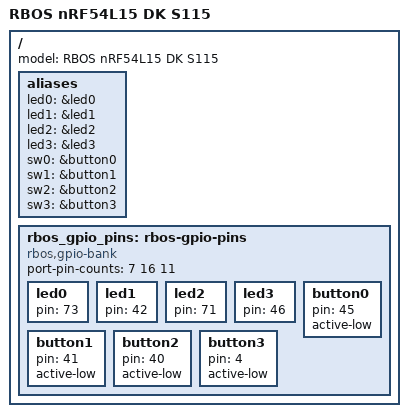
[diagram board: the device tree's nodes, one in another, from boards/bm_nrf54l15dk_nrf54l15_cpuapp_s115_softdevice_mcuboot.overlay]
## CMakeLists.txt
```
cmake_minimum_required(VERSION 3.20.0)

list(PREPEND EXTRA_CONF_FILE "${CMAKE_CURRENT_SOURCE_DIR}/common.conf")
find_package(Zephyr REQUIRED HINTS $ENV{ZEPHYR_BASE})
project(rbos)
zephyr_include_directories(include)

if(NOT DEFINED SYSBUILD)
  message(FATAL_ERROR "This must be built with sysbuild.")
endif()
if(NOT CONFIG_BOARD_BM_NRF54L15DK_NRF54L15_CPUAPP_S115_SOFTDEVICE_MCUBOOT)
  message(FATAL_ERROR "RBOS requires the nRF54L15 DK S115 MCUboot board target.")
endif()
if(NOT CONFIG_MCUBOOT_BOOTLOADER_MODE_FIRMWARE_UPDATER)
  message(FATAL_ERROR "Invalid MCUboot mode selected.")
endif()

zephyr_get(RBOS_PREFLIGHT SYSBUILD LOCAL)
if(RBOS_PREFLIGHT)
  target_sources(app PRIVATE ../tools/bm-build/preflight.c)
  return()
endif()

if(CONFIG_LTO OR CMAKE_INTERPROCEDURAL_OPTIMIZATION OR
   "${CMAKE_C_FLAGS} ${CMAKE_C_FLAGS_DEBUG} ${CMAKE_C_FLAGS_RELEASE}" MATCHES "-flto")
  message(FATAL_ERROR "RBOS supervisor requires separate translation units: LTO is unsupported")
endif()
foreach(config DEBUG RELEASE RELWITHDEBINFO MINSIZEREL)
  if(CMAKE_INTERPROCEDURAL_OPTIMIZATION_${config} OR CMAKE_C_FLAGS_${config} MATCHES "-flto")
    message(FATAL_ERROR "RBOS supervisor requires separate translation units: LTO is unsupported")
  endif()
endforeach()
include(cmake/mrubyc.cmake)
zephyr_ld_options(-Wl,--wrap=mrbc_vm_run)
target_include_directories(app PRIVATE ../src/platform/nrf)
target_sources(app PRIVATE ../src/platform/nrf/backend.c)
target_sources(app PRIVATE ../src/platform/nrf/adc.c)
target_sources(app PRIVATE ../src/platform/nrf/gpio.c)
target_sources(app PRIVATE ../src/platform/nrf/button.c)
target_sources(app PRIVATE src/main.c src/runtime.c src/ble.c src/resources.c src/hal/hal.c)
target_sources(app PRIVATE src/resource_probe.c)
target_sources(app PRIVATE src/supervisor.c)
target_sources(app PRIVATE src/ble_name.c)
target_sources(app PRIVATE src/mcumgr_reset.c)
target_sources(app PRIVATE src/fatal.c)
target_sources(app PRIVATE ../src/platform/nrf/wdt.c)
target_sources_ifdef(CONFIG_RBOS_SATURATION_FIXTURE app PRIVATE src/saturation_fixture.c)
target_sources_ifdef(CONFIG_RBOS_RETENTION_FIXTURE app PRIVATE src/retention_fixture.c)
```

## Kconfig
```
config NRFX_RESERVED_RESOURCES_HEADER
	default "rbos_reserved_resources.h"

menu "RBOS application"

config RBOS_BLE_NAME_PREFIX
	string "BLE device name prefix (1-21 bytes)"
	default "RBOS"
	help
	  Prefix for the DEVICEID-derived name. The suffix uses five bytes.
	  Names must fit legacy advertising with the three-byte Flags field.
	  Empty or overlong prefixes are rejected during BLE initialization.

config RBOS_WDT
	bool "Foreground progress watchdog"
	default y
	select NRFX_WDT

config RBOS_WDT_TIMEOUT_MS
	int "Watchdog timeout (ms)"
	range 100 60000
	default 2000

config RBOS_FATAL_REBOOT
	bool "Reboot after fatal instead of halting"
	select REBOOT
	depends on RBOS_WDT

config RBOS_FATAL_FLUSH_MS
	int "Fatal log flush deadline (ms)"
	range 1 1000
	default 100

config RBOS_FAULT_WDT
	bool "Stall native supervisor to exercise watchdog reset"
	depends on RBOS_WDT && DEBUG_OPTIMIZATIONS && !RBOS_FATAL_REBOOT
	default n

config RBOS_GPIO
	bool "RBOS board GPIO and Button API"
	default y

config RBOS_PERIPHERAL_EXERCISE
	bool "Run the P2 LED/Button diagnostic task after selftests"
	default y
	depends on RBOS_GPIO && !RBOS_TEST_PROFILE_OOM

config RBOS_SATURATION_FIXTURE
	bool "A7 TIMER/PORT and synthetic ring saturation fixture"
	depends on RBOS_GPIO && !RBOS_TEST_PROFILE_OOM && !RBOS_FAULT_WDT
	select NRFX_TIMER
	select NRFX_GPPI
	default n

config RBOS_RETENTION_FIXTURE
	bool "A7 storage0 retention fixture"
	depends on !RBOS_TEST_PROFILE_OOM && !RBOS_FAULT_WDT
	select BM_STORAGE
	select RING_BUFFER
	select CRC
	default n

config RBOS_RETENTION_SEED
	bool "Allow one explicit seed with physical Button1 held at boot"
	depends on RBOS_RETENTION_FIXTURE
	default n

config RBOS_RETENTION_NONCE
	hex "Retention trial identifier (same nonzero value in images A and B)"
	depends on RBOS_RETENTION_FIXTURE
	default 0

choice RBOS_TEST_PROFILE
	prompt "Ruby test profile"
	default RBOS_TEST_PROFILE_SELFTEST

config RBOS_TEST_PROFILE_SELFTEST
	bool "User selftests"

config RBOS_TEST_PROFILE_STRESS
	bool "Selftests followed by always-ready spinners"

config RBOS_TEST_PROFILE_OOM
	bool "Retained allocations until fatal pool exhaustion"

endchoice

config RBOS_MAX_VM_COUNT
	int "Maximum number of Ruby VMs"
	range 4 32
	default 8

config RBOS_VM_POOL_SIZE
	int "Ruby VM memory pool size"
	range 16384 131072
	default 65536

config RBOS_TIMESLICE_TICK_COUNT
	int "Ruby VM timeslice (ticks)"
	range 1 255
	default 1

config RBOS_SERVICE_INTERVAL_MS
	int "Native supervisor interval (ms)"
	range 1 1000
	default 10

config RBOS_STATS_INTERVAL_MS
	int "Runtime statistics interval (ms)"
	range 100 3600000
	default 10000

config RBOS_VM_NDEBUG
	bool "Disable assertions in mruby/c sources"

module=RBOS
module-str=RBOS
source "$(ZEPHYR_BASE)/subsys/logging/Kconfig.template.log_config"

endmenu

source "Kconfig.zephyr"
```

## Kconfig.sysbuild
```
source "$(ZEPHYR_BASE)/share/sysbuild/Kconfig"

config RBOS_RELEASE
 bool "Require an external release signing key"
 default n
```

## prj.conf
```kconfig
CONFIG_DEBUG_OPTIMIZATIONS=y
CONFIG_RBOS_FATAL_REBOOT=n
```

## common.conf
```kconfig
CONFIG_LOG=y
CONFIG_LOG_BACKEND_BM_UARTE=y
CONFIG_CLOCK_CONTROL=y
CONFIG_NRFX_SAADC=y
CONFIG_NRFX_GPIOTE=y
CONFIG_NRFX_GPIOTE_NUM_OF_EVT_HANDLERS=4
CONFIG_SOFTDEVICE=y
CONFIG_CRC=y
CONFIG_MAIN_STACK_SIZE=8192
CONFIG_INIT_STACKS=y
CONFIG_BM_TIMER=y
CONFIG_BM_SCHEDULER=y
CONFIG_NRF_SDH_DISPATCH_MODEL_SCHED=y
CONFIG_BM_SCHEDULER_BUF_SIZE=512
CONFIG_NRF_SDH_BLE_LOG_SD_RAM_USAGE=y
CONFIG_NRF_SECURITY=y
CONFIG_MBEDTLS_PSA_CRYPTO_C=y
CONFIG_PSA_WANT_GENERATE_RANDOM=y
CONFIG_BLE_ADV=y
CONFIG_BLE_ADV_RESTART_ON_DISCONNECT=y
CONFIG_BLE_ADV_FAST_ADVERTISING=y
CONFIG_BLE_ADV_FAST_ADVERTISING_TIMEOUT=1000
CONFIG_BLE_ADV_SLOW_ADVERTISING=y
CONFIG_BLE_ADV_SLOW_ADVERTISING_TIMEOUT=0
CONFIG_BLE_CONN_PARAMS=y
CONFIG_BLE_CONN_PARAMS_AUTO_ATT_MTU=y
CONFIG_NRF_SDH_BLE_GATT_MAX_MTU_SIZE=247
CONFIG_BLE_CONN_PARAMS_INITIATE_ATT_MTU_EXCHANGE=n
CONFIG_BLE_CONN_PARAMS_AUTO_DATA_LENGTH=y
CONFIG_BLE_CONN_PARAMS_DATA_LENGTH_TX=251
CONFIG_BLE_CONN_PARAMS_DATA_LENGTH_RX=251
CONFIG_BLE_CONN_PARAMS_INITIATE_DATA_LENGTH_UPDATE=n
CONFIG_BLE_CONN_PARAMS_AUTO_GAP_CONN_PARAM_UPDATE=n
CONFIG_BLE_CONN_PARAMS_LOG_LEVEL_WRN=y

CONFIG_NRF_SDH_BLE_VS_UUID_COUNT=2
CONFIG_ZCBOR=y
CONFIG_NET_BUF=y
CONFIG_ZEPHYR_QUEUE=y
CONFIG_NCS_BM_MCUMGR=y
CONFIG_BLE_MCUMGR=y
CONFIG_MCUBOOT_BOOTUTIL_LIB=y
CONFIG_MCUMGR_TRANSPORT_REASSEMBLY=y
CONFIG_MCUMGR_MGMT_NOTIFICATION_HOOKS=y
CONFIG_MCUMGR_GRP_OS=y
CONFIG_MCUMGR_GRP_OS_RESET_HOOK=y
CONFIG_MCUMGR_GRP_OS_RESET_BOOT_MODE=n
CONFIG_MCUMGR_GRP_OS_ECHO=n
CONFIG_MCUMGR_GRP_OS_MCUMGR_PARAMS=n
CONFIG_MCUMGR_GRP_OS_BOOTLOADER_INFO=n
CONFIG_MCUMGR_GRP_OS_INFO=n
CONFIG_MCUMGR_GRP_IMG=n
CONFIG_MCUMGR_GRP_SETTINGS=n
CONFIG_RETAINED_MEM=y
CONFIG_RETENTION=y
CONFIG_RETENTION_BOOT_MODE=y
CONFIG_REBOOT=y
```

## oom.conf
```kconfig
CONFIG_RBOS_TEST_PROFILE_OOM=y
```

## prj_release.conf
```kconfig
CONFIG_SIZE_OPTIMIZATIONS=y
CONFIG_RBOS_FATAL_REBOOT=y
CONFIG_RBOS_VM_NDEBUG=y
```

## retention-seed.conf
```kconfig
CONFIG_RBOS_RETENTION_FIXTURE=y
CONFIG_RBOS_RETENTION_SEED=y
CONFIG_RBOS_PERIPHERAL_EXERCISE=n
```

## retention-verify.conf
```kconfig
CONFIG_RBOS_RETENTION_FIXTURE=y
CONFIG_RBOS_PERIPHERAL_EXERCISE=n
```

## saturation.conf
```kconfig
CONFIG_RBOS_SATURATION_FIXTURE=y
CONFIG_RBOS_PERIPHERAL_EXERCISE=n
```

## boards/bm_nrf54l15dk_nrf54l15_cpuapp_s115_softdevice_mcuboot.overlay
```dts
/ {
	model = "RBOS nRF54L15 DK S115";
	aliases {
		led0 = &led0;
		led1 = &led1;
		led2 = &led2;
		led3 = &led3;
		sw0 = &button0;
		sw1 = &button1;
		sw2 = &button2;
		sw3 = &button3;
	};
	rbos_gpio_pins: rbos-gpio-pins {
		compatible = "rbos,gpio-bank";
		port-pin-counts = <7 16 11>;
		led0: led0 { pin = <73>; };
		led1: led1 { pin = <42>; };
		led2: led2 { pin = <71>; };
		led3: led3 { pin = <46>; };
		button0: button0 { pin = <45>; active-low; };
		button1: button1 { pin = <41>; active-low; };
		button2: button2 { pin = <40>; active-low; };
		button3: button3 { pin = <4>; active-low; };
	};
};
```

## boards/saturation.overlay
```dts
&button0 {
	pin = <43>;
};
```

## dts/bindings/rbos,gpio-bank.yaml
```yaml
description: RBOS native GPIO metadata (no Zephyr GPIO driver)
compatible: "rbos,gpio-bank"
properties:
  port-pin-counts:
    type: array
    required: true
child-binding:
  description: Board-reviewed native pin
  properties:
    pin:
      type: int
      required: true
    active-low:
      type: boolean
```

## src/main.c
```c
#include <app_version.h>
#include <zephyr/kernel.h>
#include <zephyr/logging/log.h>
#include <zephyr/logging/log_ctrl.h>
#include "mrubyc.h"
#include "rbos/bindings.h"
#include "backend.h"
#include "embedded.h"
#include "runtime.h"
#include "supervisor.h"
#include "status_led.h"
#include "rbos/watchdog.h"
#include "rbos_fixture.h"

LOG_MODULE_REGISTER(rbos, CONFIG_RBOS_LOG_LEVEL);
static uint8_t vm_pool[CONFIG_RBOS_VM_POOL_SIZE] __aligned(8);

int main(void)
{
	rbos_stack_paint();
	LOG_INF("RBOS %s", APP_VERSION_EXTENDED_STRING);
	rbos_reset_reason_log();
	rbos_status_led(true);

	if (rbos_resources_probe()) mrbc_hal_abort("BM scheduler capacity probe failed\n");
	if (rbos_ble_init()) mrbc_hal_abort("BLE initialization failed\n");
#if defined(CONFIG_RBOS_RETENTION_FIXTURE)
	rbos_retention_start();
#endif
	rbos_resources_log();
	mrbc_init(vm_pool, sizeof(vm_pool));
	rbos_define_classes(rbos_nrf_backend());
	for (unsigned int i = 0; i < rbos_task_count; ++i) {
		mrbc_tcb *task = mrbc_create_task(rbos_tasks[i].bytecode, NULL);
		if (!task) mrbc_hal_abort("Cannot create embedded task\n");
		mrbc_set_task_name(task, rbos_tasks[i].name);
	}
	if (rbos_supervisor_start()) mrbc_hal_abort("Cannot start watchdog\n");
	rbos_status_led(false);
	int status = mrbc_run();
	LOG_INF("Ruby scheduler returned %d; native supervisor continues", status);
	while (1) {
		rbos_supervisor_poll(true);
		k_cpu_idle();
	}
}
```

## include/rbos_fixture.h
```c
#ifndef RBOS_FIXTURE_H
#define RBOS_FIXTURE_H

#include <stdbool.h>
#include <stdint.h>

#if defined(CONFIG_RBOS_SATURATION_FIXTURE)
#include <zephyr/devicetree.h>
#define RBOS_FIXTURE_PIN DT_PROP(DT_ALIAS(sw0), pin)
int rbos_fixture_connect(uint32_t task_address);
void rbos_fixture_disconnect(void);
void rbos_fixture_begin(uint32_t pin, uint32_t generation);
void rbos_fixture_irq(void);
void rbos_fixture_edge(uint32_t pin, uint32_t level, bool accepted);
void rbos_fixture_delivery(uint32_t pin, uint32_t level, uint32_t count);
bool rbos_fixture_holds_events(void);
void rbos_fixture_poll(void);
#endif

#if defined(CONFIG_RBOS_RETENTION_FIXTURE)
void rbos_retention_start(void);
void rbos_retention_poll(void);
#endif

#endif
```

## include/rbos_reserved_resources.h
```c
#ifndef RBOS_RESERVED_RESOURCES_H
#define RBOS_RESERVED_RESOURCES_H

#include <nrf_sd_def.h>

#if !defined(CONFIG_SOFTDEVICE_S115) || defined(CONFIG_BT_LL_SOFTDEVICE) || defined(CONFIG_MPSL)
#error "RBOS resource reservations require the standalone S115 SoftDevice"
#endif

#define NRFX_DPPI00_CHANNELS_USED_BY_BT_CTLR SD_DPPIC00_CHANNELS_USED
#define NRFX_DPPI10_CHANNELS_USED_BY_BT_CTLR SD_DPPIC10_CHANNELS_USED
#define NRFX_DPPI20_CHANNELS_USED_BY_BT_CTLR SD_DPPIC20_CHANNELS_USED
#define NRFX_PPIB_00_10_CHANNELS_USED_BY_BT_CTLR \
  (SD_PPIB00_CHANNELS_USED | SD_PPIB10_CHANNELS_USED)
#define NRFX_PPIB_11_21_CHANNELS_USED_BY_BT_CTLR \
  (SD_PPIB11_CHANNELS_USED | SD_PPIB21_CHANNELS_USED)

#include <nrfx_reserved_resources_ncs.h>

#endif
```

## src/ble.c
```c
#include <string.h>
#include <hal/nrf_ficr.h>
#include <ble_gatts.h>
#include <bm/bluetooth/ble_adv.h>
#include <bm/bluetooth/services/ble_mcumgr.h>
#include <bm/softdevice_handler/nrf_sdh.h>
#include <bm/softdevice_handler/nrf_sdh_ble.h>
#include <zephyr/logging/log.h>
#include "runtime.h"
#include "rbos/ble_name.h"
#include "mcumgr_reset.h"

LOG_MODULE_REGISTER(rbos_ble, CONFIG_RBOS_LOG_LEVEL);
BLE_ADV_DEF(advertising);

static void on_ble_event(const ble_evt_t *evt, void *context)
{
	ARG_UNUSED(context);
	uint32_t result = NRF_SUCCESS;
	switch (evt->header.evt_id) {
	case BLE_GAP_EVT_CONNECTED:
		LOG_INF("BLE connected");
		rbos_mcumgr_connected(evt->evt.gap_evt.conn_handle);
		break;
	case BLE_GAP_EVT_DISCONNECTED:
		LOG_INF("BLE disconnected reason=0x%02x", evt->evt.gap_evt.params.disconnected.reason);
		rbos_mcumgr_disconnected(evt->evt.gap_evt.conn_handle);
		break;
	case BLE_GATTS_EVT_HVN_TX_COMPLETE:
		rbos_mcumgr_notification_sent(evt->evt.gatts_evt.conn_handle);
		break;
	case BLE_GAP_EVT_PHY_UPDATE_REQUEST:
		LOG_INF("BLE PHY request tx=0x%02x rx=0x%02x",
			evt->evt.gap_evt.params.phy_update_request.peer_preferred_phys.tx_phys,
			evt->evt.gap_evt.params.phy_update_request.peer_preferred_phys.rx_phys);
		break;
	case BLE_GAP_EVT_PHY_UPDATE:
		LOG_INF("BLE PHY update status=0x%02x", evt->evt.gap_evt.params.phy_update.status);
		break;
	case BLE_GAP_EVT_DATA_LENGTH_UPDATE_REQUEST:
		LOG_INF("BLE data length request tx=%u rx=%u",
			evt->evt.gap_evt.params.data_length_update_request.peer_params.max_tx_octets,
			evt->evt.gap_evt.params.data_length_update_request.peer_params.max_rx_octets);
		break;
	case BLE_GAP_EVT_DATA_LENGTH_UPDATE:
		LOG_INF("BLE data length updated tx=%u rx=%u",
			evt->evt.gap_evt.params.data_length_update.effective_params.max_tx_octets,
			evt->evt.gap_evt.params.data_length_update.effective_params.max_rx_octets);
		break;
	case BLE_GATTS_EVT_EXCHANGE_MTU_REQUEST:
		LOG_INF("BLE ATT MTU request rx=%u", evt->evt.gatts_evt.params.exchange_mtu_request.client_rx_mtu);
		break;
	case BLE_GATTS_EVT_SYS_ATTR_MISSING:
		LOG_INF("BLE system attributes missing");
		result = sd_ble_gatts_sys_attr_set(evt->evt.gatts_evt.conn_handle, NULL, 0, 0);
		break;
	case BLE_GAP_EVT_SEC_PARAMS_REQUEST:
		LOG_INF("BLE security parameters requested; pairing unsupported");
		result = sd_ble_gap_sec_params_reply(evt->evt.gap_evt.conn_handle,
			BLE_GAP_SEC_STATUS_PAIRING_NOT_SUPP, NULL, NULL);
		break;
	case BLE_GAP_EVT_SEC_INFO_REQUEST:
		LOG_INF("BLE security information requested; no stored bond");
		result = sd_ble_gap_sec_info_reply(evt->evt.gap_evt.conn_handle, NULL);
		break;
	case BLE_GATTS_EVT_TIMEOUT:
		LOG_INF("BLE GATTS timeout source=%u", evt->evt.gatts_evt.params.timeout.src);
		break;
	default:
		break;
	}
	if (result) LOG_ERR("BLE reply event=0x%04x error=%#x", evt->header.evt_id, result);
}
NRF_SDH_BLE_OBSERVER(rbos_ble, on_ble_event, NULL, USER_LOW);

static void on_adv_event(struct ble_adv *adv, const struct ble_adv_evt *evt)
{
	ARG_UNUSED(adv);
	if (evt->evt_type == BLE_ADV_EVT_ERROR) LOG_ERR("Advertising error %#x", evt->error.reason);
}

int rbos_ble_init(void)
{
	int err = nrf_sdh_enable_request();
	if (err) return err;
	err = nrf_sdh_ble_enable(CONFIG_NRF_SDH_BLE_CONN_TAG);
	if (err) return err;
	ble_gap_conn_sec_mode_t security;
	BLE_GAP_CONN_SEC_MODE_SET_NO_ACCESS(&security);
	uint8_t device_id[8];
	char name[RBOS_BLE_NAME_CAPACITY];
	rbos_ble_device_id_bytes(nrf_ficr_deviceid_get(NRF_FICR, 0),
	                         nrf_ficr_deviceid_get(NRF_FICR, 1), device_id);
	err = rbos_ble_name_generate(name, sizeof(name), CONFIG_RBOS_BLE_NAME_PREFIX, device_id);
	if (err) return err;
	uint32_t result = sd_ble_gap_device_name_set(&security, name, strlen(name));
	if (result) return -EIO;
	err = rbos_mcumgr_init();
	if (err) return err;
	ble_uuid_t uuid = {
		.uuid = BLE_MCUMGR_SERVICE_UUID_SUB,
		.type = ble_mcumgr_service_uuid_type(),
	};
	struct ble_adv_config config = {
		.conn_cfg_tag = CONFIG_NRF_SDH_BLE_CONN_TAG,
		.evt_handler = on_adv_event,
		.adv_data = {
			.name_type = BLE_ADV_DATA_FULL_NAME,
			.flags = BLE_GAP_ADV_FLAGS_LE_ONLY_GENERAL_DISC_MODE,
		},
		.sr_data.uuid_lists.complete = { .uuid = &uuid, .len = 1 },
	};
	result = ble_adv_init(&advertising, &config);
	if (result) return -EIO;
	result = ble_adv_start(&advertising, BLE_ADV_MODE_FAST);
	return result ? -EIO : 0;
}
```

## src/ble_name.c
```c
#include <errno.h>
#include <stdio.h>
#include <string.h>
#include <zephyr/sys/crc.h>
#include "rbos/ble_name.h"

void rbos_ble_device_id_bytes(uint32_t word0, uint32_t word1, uint8_t bytes[8])
{
	for (unsigned int i = 0; i < 4; ++i) {
		bytes[i] = word1 >> (24 - 8 * i);
		bytes[4 + i] = word0 >> (24 - 8 * i);
	}
}

int rbos_ble_name_generate(char *name, size_t capacity, const char *prefix,
                          const uint8_t device_id[8])
{
	if (!name || !prefix || !device_id) return -EINVAL;
	size_t length = strlen(prefix);
	if (!length || length > RBOS_BLE_NAME_MAX_PREFIX) return -EINVAL;
	if (capacity < length + 6) return -ENOSPC;
	uint16_t crc = crc16_reflect(0x9eb2, 0xffff, device_id, 8);
	int result = snprintf(name, capacity, "%s_%04X", prefix, (unsigned int)crc);
	return result < 0 ? -EIO : 0;
}
```

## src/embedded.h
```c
#ifndef RBOS_EMBEDDED_H
#define RBOS_EMBEDDED_H
#include <stdint.h>
struct rbos_embedded_task {
	const char *name;
	const uint8_t *bytecode;
};
extern const struct rbos_embedded_task rbos_tasks[];
extern const unsigned int rbos_task_count;
#endif
```

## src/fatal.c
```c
#include <bm/bm_timer.h>
#include <zephyr/kernel.h>
#include <zephyr/fatal.h>
#include <zephyr/logging/log_ctrl.h>
#include <zephyr/sys/printk.h>
#include <zephyr/sys/reboot.h>
#include "mrubyc.h"
#include "rbos/watchdog.h"
#include "status_led.h"

#if CONFIG_RBOS_FATAL_REBOOT
static struct bm_timer fatal_deadline;

static void fatal_reboot(void *context)
{
	ARG_UNUSED(context);
	sys_reboot(SYS_REBOOT_COLD);
}
#endif

_Noreturn void mrbc_hal_abort(const char *message)
{
	rbos_status_led(true);
#if CONFIG_RBOS_FATAL_REBOOT
	if (bm_timer_init(&fatal_deadline, BM_TIMER_MODE_SINGLE_SHOT, fatal_reboot) ||
	    bm_timer_start(&fatal_deadline, BM_TIMER_MS_TO_TICKS(CONFIG_RBOS_FATAL_FLUSH_MS), NULL))
		sys_reboot(SYS_REBOOT_COLD);
#else
	rbos_wdt_stop();
#endif
	mrbc_hal_flush(2);
	printk("RBOS fatal: %s", message ? message : "Ruby abort\n");
	LOG_PANIC();
#if CONFIG_RBOS_FATAL_REBOOT
	sys_reboot(SYS_REBOOT_COLD);
#else
	k_fatal_halt(K_ERR_KERNEL_PANIC);
#endif
	CODE_UNREACHABLE;
}
```

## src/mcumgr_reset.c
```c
#include <errno.h>
#include <stdbool.h>
#include <ble_gap.h>
#include <bm/bluetooth/services/ble_mcumgr.h>
#include <zephyr/mgmt/mcumgr/mgmt/callbacks.h>
#include <zephyr/retention/bootmode.h>
#include <zephyr/sys/reboot.h>
#include "mcumgr_reset.h"

static uint16_t connected_handle = BLE_CONN_HANDLE_INVALID;
static uint16_t reset_handle = BLE_CONN_HANDLE_INVALID;
static bool pending;
static bool notification_sent;
static bool disconnected;
static bool disconnect_requested;

static enum mgmt_cb_return reset_hook(uint32_t event, enum mgmt_cb_return previous,
                                    int32_t *rc, uint16_t *group, bool *abort_more,
                                    void *data, size_t size)
{
	(void)group;
	(void)data;
	(void)size;
	if (event != MGMT_EVT_OP_OS_MGMT_RESET) return MGMT_CB_OK;
	if (previous != MGMT_CB_OK) return previous;
	*abort_more = true;
	if (pending || connected_handle == BLE_CONN_HANDLE_INVALID) {
		*rc = MGMT_ERR_EBUSY;
	} else if (bootmode_set(BOOT_MODE_TYPE_BOOTLOADER)) {
		*rc = MGMT_ERR_EUNKNOWN;
	} else {
		reset_handle = connected_handle;
		pending = true;
		notification_sent = false;
		disconnected = false;
		disconnect_requested = false;
		*rc = MGMT_ERR_EOK;
	}
	return MGMT_CB_ERROR_RC;
}

static struct mgmt_callback reset_callback = {
	.callback = reset_hook,
	.event_id = MGMT_EVT_OP_OS_MGMT_RESET,
};

int rbos_mcumgr_init(void)
{
	struct ble_mcumgr_config config = {
		.sec_mode = BLE_MCUMGR_CONFIG_SEC_MODE_DEFAULT,
	};
	if (ble_mcumgr_init(&config)) return -EIO;
	mgmt_callback_register(&reset_callback);
	return 0;
}

void rbos_mcumgr_connected(uint16_t handle)
{
	connected_handle = handle;
}

void rbos_mcumgr_disconnected(uint16_t handle)
{
	if (handle == connected_handle) connected_handle = BLE_CONN_HANDLE_INVALID;
	if (pending && handle == reset_handle) disconnected = true;
}

void rbos_mcumgr_notification_sent(uint16_t handle)
{
	if (pending && handle == reset_handle) notification_sent = true;
}

void rbos_mcumgr_poll(void)
{
	if (!pending) return;
	if (disconnected) {
		pending = false;
		sys_reboot(SYS_REBOOT_WARM);
		return;
	}
	if (!notification_sent || disconnect_requested) return;
	uint32_t result = sd_ble_gap_disconnect(reset_handle,
		BLE_HCI_REMOTE_USER_TERMINATED_CONNECTION);
	if (result == NRF_SUCCESS) disconnect_requested = true;
}
```

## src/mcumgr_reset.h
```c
#ifndef RBOS_MCUMGR_RESET_H
#define RBOS_MCUMGR_RESET_H

#include <stdint.h>

int rbos_mcumgr_init(void);
void rbos_mcumgr_connected(uint16_t handle);
void rbos_mcumgr_disconnected(uint16_t handle);
void rbos_mcumgr_notification_sent(uint16_t handle);
void rbos_mcumgr_poll(void);

#endif
```

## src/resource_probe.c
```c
#include <errno.h>
#include <string.h>
#include <bm/bm_scheduler.h>
#include <zephyr/logging/log.h>
#include "runtime.h"

LOG_MODULE_REGISTER(rbos_probe, CONFIG_RBOS_LOG_LEVEL);
static unsigned int delivered;
static bool corrupt;
static uint8_t payload[64];

static void consume(void *data, size_t length)
{
  ++delivered;
  if (length && memcmp(data, payload, length)) corrupt = true;
}

int rbos_resources_probe(void)
{
  /* Run before SoftDevice enable and VM creation, never against a live SD queue. */
  memset(payload, 0xa5, sizeof(payload));
  const size_t lengths[] = { 0, 16, 64 };
  for (unsigned int i = 0; i < 3; ++i) {
    size_t length = lengths[i];
    unsigned int accepted = 0;
    delivered = 0;
    corrupt = false;
    int result = 0;
    for (; accepted < 64; ++accepted) {
      result = bm_scheduler_defer(consume, length ? payload : NULL, length);
      if (result) break;
    }
    bm_scheduler_process();
    bool valid = (result == -ENOMEM || (result == 0 && accepted == 64)) &&
      accepted > 0 && delivered == accepted && !corrupt;
    if (!bm_scheduler_defer(consume, length ? payload : NULL, length)) {
      bm_scheduler_process();
      valid = valid && delivered == accepted + 1 && !corrupt;
    } else valid = false;
    LOG_INF("scheduler_probe payload=%u accepted=%u delivered=%u exhausted=%u recovered=%u",
      (unsigned int)length, accepted, delivered, result == -ENOMEM, valid);
    if (!valid) return -EIO;
  }
  return 0;
}
```

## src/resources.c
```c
#include <bm/bm_irq.h>
#include <bm/bm_scheduler.h>
#include <bm/softdevice_handler/nrf_sdh_ble.h>
#include <nrfx.h>
#include CONFIG_NRFX_RESERVED_RESOURCES_HEADER
#include <zephyr/logging/log.h>
#include <zephyr/sys/util.h>
#include "runtime.h"

LOG_MODULE_REGISTER(rbos_resources, CONFIG_RBOS_LOG_LEVEL);

BUILD_ASSERT(IS_ENABLED(CONFIG_SOFTDEVICE_S115), "RBOS requires S115");
BUILD_ASSERT(IS_ENABLED(CONFIG_LOG_BACKEND_BM_UARTE), "P2 console requires BM UARTE");
BUILD_ASSERT(!IS_ENABLED(CONFIG_SHELL) && !IS_ENABLED(CONFIG_NFC_T2T_NRFXLIB) &&
             !IS_ENABLED(CONFIG_NFC_T4T_NRFXLIB), "Shell/NFC require a new resource audit");
BUILD_ASSERT(IS_ENABLED(CONFIG_NRF_SDH_DISPATCH_MODEL_SCHED), "RBOS requires SCHED dispatch");
BUILD_ASSERT(IS_ENABLED(CONFIG_BM_SCHEDULER), "RBOS requires the BM scheduler");
BUILD_ASSERT(CONFIG_BM_SCHEDULER_BUF_SIZE >= 512, "BM scheduler heap below audited baseline");
BUILD_ASSERT(IS_ENABLED(CONFIG_ZERO_LATENCY_IRQS) && CONFIG_ZERO_LATENCY_LEVELS == 1 &&
             __NVIC_PRIO_BITS == 3 && BM_IRQ_OFFSET == 2,
             "Ruby HAL requires BASEPRI to mask NVIC priorities 2 through 7");
BUILD_ASSERT(CONFIG_BM_TIMER_IRQ_PRIO >= 2 && CONFIG_BM_TIMER_IRQ_PRIO <= 7,
             "BM timer must use an application IRQ priority");
BUILD_ASSERT(CONFIG_LOG_BACKEND_BM_UARTE_IRQ_PRIO >= 2 &&
             CONFIG_LOG_BACKEND_BM_UARTE_IRQ_PRIO <= 7,
             "Console must use an application IRQ priority");
BUILD_ASSERT((NRFX_GRTC_CONFIG_ALLOWED_CC_CHANNELS_MASK & SD_GRTC_CC_CHANNELS_USED) == 0,
             "GRTC allocator overlaps SoftDevice channels");
BUILD_ASSERT((NRFX_GRTC_CONFIG_ALLOWED_CC_CHANNELS_MASK & BIT(0)) != 0 &&
             (SD_GRTC_CC_CHANNELS_USED & BIT(0)) == 0 && SD_GRTC_IRQn_USED != GRTC_2_IRQn,
             "BM system timer requires GRTC channel 0 and GRTC_2");

#define CHECK_RESERVED(actual, reserved) \
  BUILD_ASSERT(((actual) & (reserved)) == (reserved), "nrfx allocator misses " #reserved)
CHECK_RESERVED(NRFX_DPPI00_CHANNELS_USED, SD_DPPIC00_CHANNELS_USED);
CHECK_RESERVED(NRFX_DPPI10_CHANNELS_USED, SD_DPPIC10_CHANNELS_USED);
CHECK_RESERVED(NRFX_DPPI20_CHANNELS_USED, SD_DPPIC20_CHANNELS_USED);
CHECK_RESERVED(NRFX_PPIB_INTERCONNECT_00_10_CHANNELS_USED,
               SD_PPIB00_CHANNELS_USED | SD_PPIB10_CHANNELS_USED);
CHECK_RESERVED(NRFX_PPIB_INTERCONNECT_11_21_CHANNELS_USED,
               SD_PPIB11_CHANNELS_USED | SD_PPIB21_CHANNELS_USED);

void rbos_resources_log(void)
{
  LOG_INF("resources sched_bytes=%u sched_header=%u service_ms=%u sd_ram=%u",
          (unsigned int)CONFIG_BM_SCHEDULER_BUF_SIZE,
          (unsigned int)sizeof(struct bm_scheduler_event),
          (unsigned int)CONFIG_RBOS_SERVICE_INTERVAL_MS,
          (unsigned int)nrf_sdh_ble_sd_ram_usage_get());
}
```

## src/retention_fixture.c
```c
#include <string.h>
#include <stddef.h>
#include <hal/nrf_gpio.h>
#include <bm/storage/bm_storage.h>
#include <zephyr/devicetree.h>
#include <zephyr/kernel.h>
#include <zephyr/logging/log.h>
#include <zephyr/sys/crc.h>
#include "rbos_fixture.h"

LOG_MODULE_REGISTER(rbos_retention, CONFIG_RBOS_LOG_LEVEL);
#define STORAGE DT_NODELABEL(storage0_partition)
#define PEER DT_NODELABEL(peer_manager_partition)
BUILD_ASSERT(CONFIG_RBOS_RETENTION_NONCE != 0, "Set a unique nonzero trial nonce in both images");
BUILD_ASSERT(IS_ENABLED(CONFIG_BM_STORAGE_BACKEND_SD), "Fixture requires SoftDevice storage");
BUILD_ASSERT(!IS_ENABLED(CONFIG_SETTINGS) && !IS_ENABLED(CONFIG_BM_ZMS), "Not settings/ZMS retention");
BUILD_ASSERT(DT_REG_SIZE(STORAGE) == 4096 && DT_REG_SIZE(PEER) == 4096, "Review partition layout");
BUILD_ASSERT(!IS_ENABLED(CONFIG_RBOS_SATURATION_FIXTURE), "Run A7 fixtures separately");

static struct bm_storage storage;
static uint32_t sentinel[8] __aligned(16);
static uint32_t peer_before;
static volatile bool pending, completed;
static volatile int result;
static int64_t deadline;
static bool finished;

static uint32_t peer_digest(void)
{
	return crc32_ieee((const uint8_t *)(uintptr_t)DT_REG_ADDR(PEER), DT_REG_SIZE(PEER));
}

static void event_handler(struct bm_storage_evt *event)
{
	if (!pending || event->id != BM_STORAGE_EVT_WRITE_RESULT || event->ctx != &storage ||
	    event->addr != 0 || event->len != sizeof(sentinel)) {
		result = -1;
	} else {
		result = event->result;
	}
	completed = true;
}

static void fail(const char *reason)
{
	LOG_ERR("p5 error=%s", reason);
	finished = true;
}

static bool verify(void)
{
	uint32_t actual[8];
	if (bm_storage_read(&storage, 0, actual, sizeof(actual)) ||
	    memcmp(actual, sentinel, sizeof(actual))) {
		fail("sentinel_missing_or_corrupt");
		return false;
	}
	return true;
}

void rbos_retention_start(void)
{
	struct bm_storage_config config = { .evt_handler = event_handler, .api = &bm_storage_sd_api,
		.addr = DT_REG_ADDR(STORAGE), .size = DT_REG_SIZE(STORAGE) };
	if (bm_storage_init(&storage, &config)) { fail("init"); return; }
	sentinel[0] = 0x52424f53;
	sentinel[1] = 1;
	sentinel[2] = CONFIG_RBOS_RETENTION_NONCE;
	sentinel[3] = 0xa7a7a7a7;
	sentinel[4] = 0x13579bdf;
	sentinel[5] = 0x2468ace0;
	sentinel[6] = 32;
	sentinel[7] = crc32_ieee((const uint8_t *)sentinel, sizeof(sentinel) - sizeof(uint32_t));
	peer_before = peer_digest();
	if (IS_ENABLED(CONFIG_RBOS_RETENTION_SEED)) {
		uint32_t pin = DT_PROP(DT_ALIAS(sw1), pin);
		uint32_t local = pin;
		NRF_GPIO_Type *port = nrf_gpio_pin_port_decode(&local);
		uint32_t saved = port->PIN_CNF[local];
		nrf_gpio_cfg_input(pin, NRF_GPIO_PIN_PULLUP);
		bool seed = nrf_gpio_pin_read(pin) == 0;
		port->PIN_CNF[local] = saved;
		if (!seed) { fail("seed_requires_held_button1"); return; }
		pending = true;
		deadline = k_uptime_get() + 10000;
		if (bm_storage_write(&storage, 0, sentinel, sizeof(sentinel), &storage)) fail("write_submit");
	}
}

void rbos_retention_poll(void)
{
	if (finished) return;
	if (pending) {
		if (!completed) {
			if (k_uptime_get() > deadline) fail("write_timeout");
			return;
		}
		if (result) { fail("write_result"); return; }
		pending = false;
	}
	if (!verify()) return;
	uint32_t peer_after = peer_digest();
	if (peer_before != peer_after) { fail("peer_changed"); return; }
	LOG_INF("p5 mode=%s nonce=%08x sentinel=%08x peer_before=%08x peer_after=%08x verified=1 writes=%u",
		IS_ENABLED(CONFIG_RBOS_RETENTION_SEED) ? "seed" : "verify", CONFIG_RBOS_RETENTION_NONCE,
		sentinel[7], peer_before, peer_after, IS_ENABLED(CONFIG_RBOS_RETENTION_SEED) ? 1 : 0);
	finished = true;
}
```

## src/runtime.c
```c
#include <string.h>
#include <bm/bm_scheduler.h>
#include <zephyr/kernel.h>
#include <zephyr/logging/log.h>
#include <zephyr/logging/log_ctrl.h>
#include "runtime.h"
#include "mcumgr_reset.h"
#include "rbos/native.h"
#include "rbos/bindings.h"
#if defined(CONFIG_RBOS_SATURATION_FIXTURE) || defined(CONFIG_RBOS_RETENTION_FIXTURE)
#include "rbos_fixture.h"
#endif

LOG_MODULE_REGISTER(rbos_runtime, CONFIG_RBOS_LOG_LEVEL);
K_THREAD_STACK_DECLARE(z_main_stack, CONFIG_MAIN_STACK_SIZE);
K_KERNEL_STACK_ARRAY_DECLARE(z_interrupt_stacks, CONFIG_MP_MAX_NUM_CPUS, CONFIG_ISR_STACK_SIZE);
static uint8_t *main_painted_end;
static unsigned int pool_max;
static unsigned int idle_count;
static unsigned int supervisor_count;
static unsigned int drain_max_us;
static int64_t last_stats;
static struct rbos_event_queue event_queue;

bool rbos_event_post(const struct rbos_event *event)
{
	unsigned int key = irq_lock();
	bool accepted = rbos_event_queue_push(&event_queue, event);
	irq_unlock(key);
	return accepted;
}

bool rbos_event_take(struct rbos_event *event)
{
#if defined(CONFIG_RBOS_SATURATION_FIXTURE)
	if (rbos_fixture_holds_events()) return false;
#endif
	unsigned int key = irq_lock();
	bool available = rbos_event_queue_pop(&event_queue, event);
	irq_unlock(key);
	return available;
}

void rbos_event_snapshot(struct rbos_event_stats *stats)
{
	unsigned int key = irq_lock();
	*stats = (struct rbos_event_stats){ event_queue.size, event_queue.overflow, event_queue.coalesced };
	irq_unlock(key);
}

void rbos_stack_paint(void)
{
	uintptr_t sp = __get_PSP();
	uint8_t *base = (uint8_t *)K_THREAD_STACK_BUFFER(z_main_stack);
	/* Leave the current frame and compiler spills untouched. */
	if (sp > (uintptr_t)base + 256) {
		main_painted_end = (uint8_t *)(sp - 256);
		memset(base, 0xaa, main_painted_end - base);
	}
}

static unsigned int stack_used(const uint8_t *base, size_t size, const uint8_t *end)
{
	const uint8_t *p = base;
	while (p < end && *p == 0xaa) ++p;
	return size - (p - base);
}

void rbos_maintenance(bool idle)
{
	if (idle) ++idle_count;
	else ++supervisor_count;
	uint32_t drain_start = k_cycle_get_32();
	bm_scheduler_process();
	rbos_mcumgr_poll();
#if defined(CONFIG_RBOS_SATURATION_FIXTURE)
	rbos_fixture_poll();
#endif
#if defined(CONFIG_RBOS_RETENTION_FIXTURE)
	rbos_retention_poll();
#endif
	rbos_bindings_service();
	uint32_t drain_us = k_cyc_to_us_floor32(k_cycle_get_32() - drain_start);
	if (drain_us > drain_max_us) drain_max_us = drain_us;
	for (int i = 0; i < 4; ++i) {
		if (!log_process()) break;
	}
	struct MRBC_ALLOC_STATISTICS pool;
	mrbc_alloc_statistics(&pool);
	if (pool.used > pool_max) pool_max = pool.used;
	int64_t now = k_uptime_get();
	if (now - last_stats < CONFIG_RBOS_STATS_INTERVAL_MS) return;
	last_stats = now;
	struct rbos_tick_stats ticks;
	rbos_tick_take_interval(&ticks);
	const uint8_t *main_base = (uint8_t *)K_THREAD_STACK_BUFFER(z_main_stack);
	const uint8_t *isr_base = (uint8_t *)K_KERNEL_STACK_BUFFER(z_interrupt_stacks[0]);
	unsigned int main_used = stack_used(main_base, CONFIG_MAIN_STACK_SIZE,
		main_painted_end ? main_painted_end : main_base);
	unsigned int isr_used = stack_used(isr_base, CONFIG_ISR_STACK_SIZE,
		isr_base + CONFIG_ISR_STACK_SIZE);
	unsigned int key = irq_lock();
	uint32_t pending = event_queue.size;
	uint32_t overflow = event_queue.overflow;
	uint32_t coalesced = event_queue.coalesced;
	irq_unlock(key);
	LOG_INF("stats tick_us=%u..%u catchups=%u ticks=%u pool=%u/%u main=%u isr=%u idle=%u supervisor=%u drain_us=%u event_pending=%u event_overflow=%u event_coalesced=%u",
		ticks.min_us, ticks.max_us, ticks.catchups, ticks.count, pool_max, pool.total,
		main_used, isr_used, idle_count, supervisor_count, drain_max_us,
		pending, overflow, coalesced);
	drain_max_us = 0;
}
```
